# A31G22x register map
Vendor: ABOV Semiconductor Co., Ltd.; Series: A31G22x; File version: 0.2
CPU: CM0PLUS r0p1, little endian, no MPU, no FPU, VTOR, 2 interrupt priority bits
Registers are 32-bit, read-write, reset 0x0 unless marked. A register's access mark holds for its fields unless they carry their own. Offsets are from the block's base; [hi:lo] are bit positions; {n}, {i} and the like mark numbered series.

## USART10 — UNIVERSAL SYNCHRONOUS/ASYNCHRONOUS RECEIVER/TRANSMITTER
Base 0x40003800
Same registers: USART11 0x40003900, USART12 0x40003A00, USART13 0x40003B00
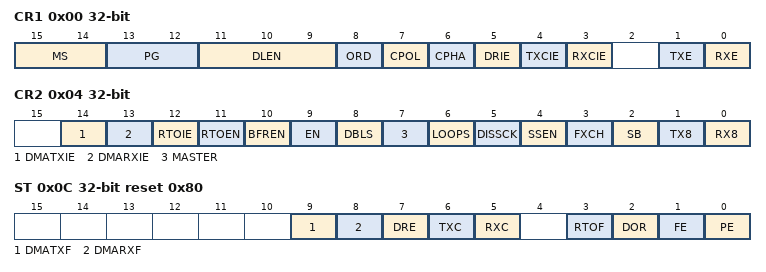
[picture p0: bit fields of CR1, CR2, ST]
0x00 CR1 — USARTn Control Register 1
  [15:14] MS — USARTn Operation Mode Selection bits
    0=ASYNC (Asynchronous Mode (UART)); 1=SYNC (Synchronous Mode); 3=SPI (SPI mode)
  [13:12] PG — Selects Parity Generation and Check method (only UART mode)
    0=NO_PARITY; 2=EVEN (Even parity); 3=ODD (Odd parity)
  [11:9] DLEN — Selects the length of data bit in a frame when Asynchronous or Synchronous mode
    {v}={v+5}BIT (v=0..3); 7=9BIT
  [8] ORD — Selects the first data bit to be transmitted (only SPI mode)
    0=LSB_FIRST; 1=MSB_FIRST
  [7] CPOL — Selects the clock polarity of ACK in synchronous or SPI mode
    0=CHANGE_AT_FALLING_EDGE (TXD Change @Rising Edge, RXD Change @Falling Edge); 1=CHANGE_AT_RISING_EDGE (TXD Change @Falling Edge, RXD Change @Rising Edge)
  [6] CPHA — (null)The CPOL and this bit determine if data are sampled on the leading or trailing edge of SCK (only SPI mode)
    0=SPL_STP (Sample / Setup); 1=STP_SPL (Setup / Sample)
  [5] DRIE — Transmit Data Register Empty Interrupt Enable bit
  [4] TXCIE — Transmit Complete Interrupt Enable bit
  [3] RXCIE — Receive Complete Interrupt Enable bit
  [1] TXE — Enables the Transmitter unit
  [0] RXE — Enables the Receiver unit
0x04 CR2 — USARTn Control Register 2
  [14] DMATXIE — DMA Tx Interrupt Enable bit
  [13] DMARXIE — DMA Rx Interrupt Enable bit
  [12] RTOIE — RTO Interrupt Enable bit
  [11] RTOEN — Active RTO Block by supplying. After RTO is occur, this bit is clear
  [10] BFREN — Activate Baud-Rate Fraction Counter Register
  [9] EN — (nActivate USARTn Block by supplyingull)
  [8] DBLS — Selects receiver sampling rate (only UART mode)
  [7] MASTER — Selects master or slave in SPI or Synchronous mode and controls the direction of SCK pin
  [6] LOOPS — Control the Loop Back mode of USARTn for test mode
  [5] DISSCK — In synchronous mode operation, selects the waveform of SCK output
  [4] SSEN — This bit controls the SSn pin operation (only SPI mode)
  [3] FXCH — SPI port function exchange control bit (only SPI mode)
  [2] SB — Selects the length of stop bit in Asynchronous or Synchronous mode
  [1] TX8 — The ninth bit of data frame in Asynchronous or Synchronous mode of operation. Write this bit first before loading the USARTn_DR register
  [0] RX8 — The ninth bit of data frame in Asynchronous or Synchronous mode of operation. Read this bit first before reading the receive buffer (only UART mode)
0x0C ST reset 0x80 (reset mask 0xE7) — USARTn Status Register
  [9] DMATXF — DMA Transmit Operation Complete flag. (DMA to USART)
  [8] DMARXF — DMA Receive Operation Complete flag. (USART to DMA)
  [7] DRE — Transmit Data Register Empty Interrupt Flag
  [6] TXC — Transmit Complete Interrupt Flag
  [5] RXC ro — Receive Complete Interrupt Flag
  [3] RTOF — Receive Time Out Interrupt flag. This bit is cleared to 0 when write 1
  [2] DOR ro — This bit is set if data OverRun occurs
  [1] FE — This bit is set if the first stop bit of next character in the receive buffer is detected as '0'. This bit is valid until the receive buffer is read (only UART mode)
  [0] PE — This bit is set if the next character in the receive buffer has a Parity Error while parity is checked. This bit is valid until the receive buffer is read (only UART mode)
0x10 BDR reset 0xFFF — USARTn Baud Rate Generation Register
  [11:0] BDATA — The value in this register is used to generate internal baud rate in UART mode or to generate SCK clock in SPI mode. To prevent malfunction, do not write '0' in UART mode and do not write '0' or '1' in synchronous or SPI mode.
0x14 DR — USARTn Data Register
  [7:0] DATA — The USART Transmit buffer and Receive buffer share the same I/O address with this DATA register. The Transmit Data Buffer is the destination for data written to the USTnDR register. Reading the USTnDR register returns the contents of the Receive Buffer. Write to this register only when the DRE flag is set. In SPI master mode, the SCK clock is generated when data are written to this register.
0x18 BFR — USARTn Baud-Rate Fraction Count Register
  [7:0] BFC — USART Baud-Rate Fraction Counter
0x1C RTO reset 0xFFFFFF — USARTn Receive Time Out Register
  [23:0] RTO — USART Receive Time Out
